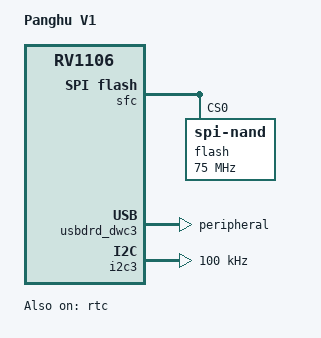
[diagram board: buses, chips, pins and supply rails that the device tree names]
// SPDX-License-Identifier: (GPL-2.0+ OR MIT)
/*
 * Copyright (c) 2022 Rockchip Electronics Co., Ltd.
 */

/dts-v1/;

#include "rv1106.dtsi"
#include "rv1106-evb.dtsi"
#include "rv1106-panghu-v1-ipc.dtsi"

/ {
	model = "Panghu V1";
	compatible = "rockchip,rv1103g-38x38-ipc-v10", "rockchip,rv1106";
};

/**********FLASH**********/
&sfc {
	status = "okay";
	flash@0 {
		compatible = "spi-nand";
		reg = <0>;
		spi-max-frequency = <75000000>;
		spi-rx-bus-width = <4>;
		spi-tx-bus-width = <1>;
	};
	
};

/**********ETH**********/
&gmac {
	status = "disabled";
};

/**********USB**********/
&usbdrd_dwc3 {
	status = "okay";
	dr_mode = "peripheral";
};

/**********I2C**********/
/* I2C3_M1 */
&i2c3 {
	status = "okay";
	clock-frequency = <100000>;
};

/* I2C1_M1 */
&i2c1 {
	status = "disabled";
	clock-frequency = <100000>;
};


/**********UART**********/
/* UART3_M1 */
&uart3 {
	status = "disabled";
};

/* UART4_M1 */
&uart4 {
	status = "disabled";
};

/**********RTC**********/
&rtc {
	status = "okay";
};
